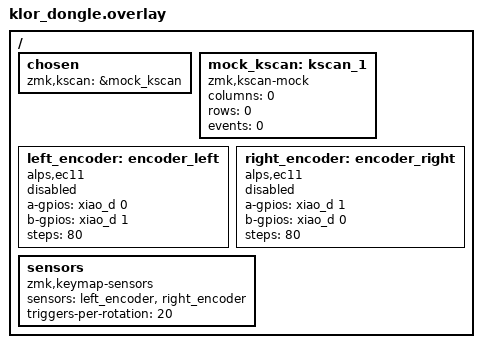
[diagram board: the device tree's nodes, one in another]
/*
 * Copyright (c) 2022 GEIST
 *
 * SPDX-License-Identifier: MIT
 */

#include "klor.dtsi"

/ {
    chosen {
        zmk,kscan = &mock_kscan;
    };

    mock_kscan: kscan_1 {
        compatible = "zmk,kscan-mock";
        columns = <0>;
        rows = <0>;
        events = <0>;
    };

    left_encoder: encoder_left {
        compatible = "alps,ec11";
        a-gpios = <&xiao_d 0 (GPIO_ACTIVE_HIGH | GPIO_PULL_UP)>;
        b-gpios = <&xiao_d 1 (GPIO_ACTIVE_HIGH | GPIO_PULL_UP)>;
        steps = <80>;
        status = "disabled";
    };

    right_encoder: encoder_right {
        compatible = "alps,ec11";
        a-gpios = <&xiao_d 1 (GPIO_ACTIVE_HIGH | GPIO_PULL_UP)>;
        b-gpios = <&xiao_d 0 (GPIO_ACTIVE_HIGH | GPIO_PULL_UP)>;
        steps = <80>;
        status = "disabled";
    };

    sensors: sensors {
        compatible = "zmk,keymap-sensors";
        sensors = <&left_encoder &right_encoder>;
        triggers-per-rotation = <20>;
    };
};
